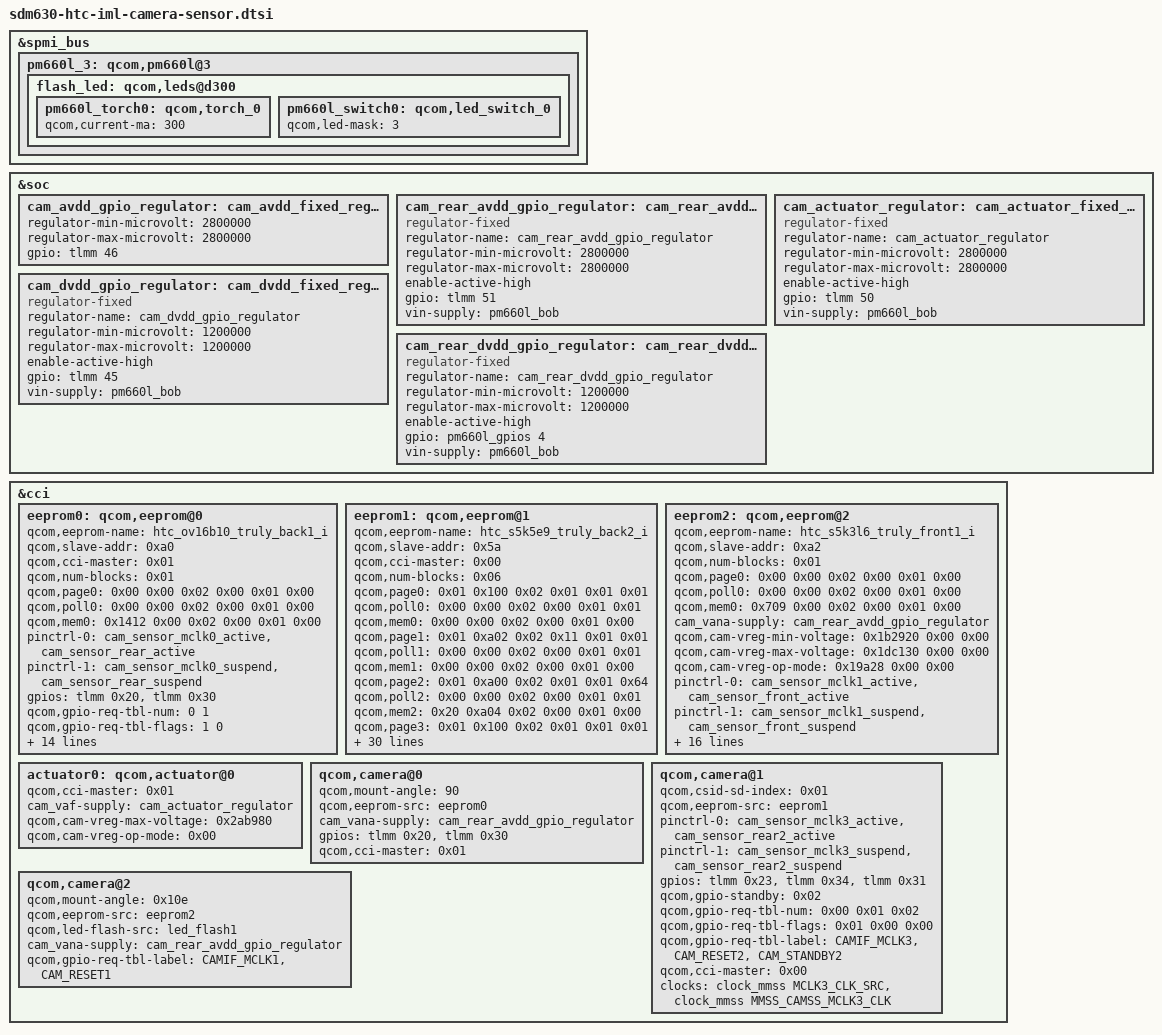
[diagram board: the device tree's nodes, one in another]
&spmi_bus {
	pm660l_3: qcom,pm660l@3 {
		flash_led: qcom,leds@d300 {
			pm660l_torch0: qcom,torch_0 {
				qcom,current-ma = <300>;
			};
			pm660l_switch0: qcom,led_switch_0 {
				qcom,led-mask = <3>;
			};
		};
	};
};

&soc {
	cam_avdd_gpio_regulator: cam_avdd_fixed_regulator {
		regulator-min-microvolt = <2800000>;
		regulator-max-microvolt = <2800000>;
		gpio = <&tlmm 46 0>;
	};
	cam_rear_avdd_gpio_regulator: cam_rear_avdd_fixed_regulator {
		compatible = "regulator-fixed";
		regulator-name = "cam_rear_avdd_gpio_regulator";
		regulator-min-microvolt = <2800000>;
		regulator-max-microvolt = <2800000>;
		enable-active-high;
		gpio = <&tlmm 51 0>;
		vin-supply = <&pm660l_bob>;
	};

	cam_actuator_regulator: cam_actuator_fixed_regulator {
		compatible = "regulator-fixed";
		regulator-name = "cam_actuator_regulator";
		regulator-min-microvolt = <2800000>;
		regulator-max-microvolt = <2800000>;
		enable-active-high;
		gpio = <&tlmm 50 0>;
		vin-supply = <&pm660l_bob>;
	};

	cam_dvdd_gpio_regulator: cam_dvdd_fixed_regulator {
		compatible = "regulator-fixed";
		regulator-name = "cam_dvdd_gpio_regulator";
		regulator-min-microvolt = <1200000>;
		regulator-max-microvolt = <1200000>;
		enable-active-high;
		gpio = <&tlmm 45 0>;
		vin-supply = <&pm660l_bob>;
	};

	cam_rear_dvdd_gpio_regulator: cam_rear_dvdd_fixed_regulator {
		compatible = "regulator-fixed";
		regulator-name = "cam_rear_dvdd_gpio_regulator";
		regulator-min-microvolt = <1200000>;
		regulator-max-microvolt = <1200000>;
		enable-active-high;
		gpio = <&pm660l_gpios 4 0>;
		vin-supply = <&pm660l_bob>;
	};
};

&cci {
	/* Only adding stuff that overwrites or extends the base SDM660 camera DTS */
	eeprom0: qcom,eeprom@0 {
		qcom,eeprom-name = "htc_ov16b10_truly_back1_i";
		qcom,slave-addr = <0xa0>;
		qcom,cci-master = <0x01>;
		qcom,num-blocks = <0x01>;
		qcom,page0 = <0x00 0x00 0x02 0x00 0x01 0x00>;
		qcom,poll0 = <0x00 0x00 0x02 0x00 0x01 0x00>;
		qcom,mem0 = <0x1412 0x00 0x02 0x00 0x01 0x00>;
		pinctrl-0 = <&cam_sensor_mclk0_active &cam_sensor_rear_active>;
		pinctrl-1 = <&cam_sensor_mclk0_suspend &cam_sensor_rear_suspend>;
		gpios = <&tlmm 0x20 0x00>,
		<&tlmm 0x30 0x00>;
		qcom,gpio-req-tbl-num = <0 1>;
		qcom,gpio-req-tbl-flags = <1 0>;
		qcom,gpio-req-tbl-label = "CAMIF_MCLK0", "CAM_RESET0";
		qcom,cam-power-seq-type = "sensor_gpio", "sensor_vreg",
		"sensor_vreg", "sensor_vreg",
		"sensor_clk", "sensor_gpio";
		qcom,cam-power-seq-val = "sensor_gpio_reset", "cam_vdig",
		"cam_vio", "cam_vana",
		"sensor_cam_mclk", "sensor_gpio_reset";
		qcom,cam-power-seq-cfg-val = <0x00 0x01 0x01 0x01 0x16e3600 0x01>;
		qcom,cam-power-seq-delay = <0x05 0x00 0x05 0x05 0x05 0x05>;
		cam_vana-supply = <&cam_rear_avdd_gpio_regulator>;
		qcom,i2c-freq-mode = <0x01>;
		/delete-property/ qcom,gpio-vaf;
	};
	
	eeprom1: qcom,eeprom@1 {
		qcom,eeprom-name = "htc_s5k5e9_truly_back2_i";
		qcom,slave-addr = <0x5a>;
		qcom,cci-master = <0x00>;
		qcom,num-blocks = <0x06>;
		qcom,page0 = <0x01 0x100 0x02 0x01 0x01 0x01>;
		qcom,poll0 = <0x00 0x00 0x02 0x00 0x01 0x01>;
		qcom,mem0 = <0x00 0x00 0x02 0x00 0x01 0x00>;
		qcom,page1 = <0x01 0xa02 0x02 0x11 0x01 0x01>;
		qcom,poll1 = <0x00 0x00 0x02 0x00 0x01 0x01>;
		qcom,mem1 = <0x00 0x00 0x02 0x00 0x01 0x00>;
		qcom,page2 = <0x01 0xa00 0x02 0x01 0x01 0x64>;
		qcom,poll2 = <0x00 0x00 0x02 0x00 0x01 0x01>;
		qcom,mem2 = <0x20 0xa04 0x02 0x00 0x01 0x00>;
		qcom,page3 = <0x01 0x100 0x02 0x01 0x01 0x01>;
		qcom,poll3 = <0x00 0x00 0x02 0x00 0x01 0x01>;
		qcom,mem3 = <0x00 0x00 0x02 0x00 0x01 0x00>;
		qcom,page4 = <0x01 0xa02 0x02 0x13 0x01 0x01>;
		qcom,poll4 = <0x00 0x00 0x02 0x00 0x01 0x01>;
		qcom,mem4 = <0x00 0x00 0x02 0x00 0x01 0x00>;
		qcom,page5 = <0x01 0xa00 0x02 0x01 0x01 0x64>;
		qcom,poll5 = <0x00 0x00 0x02 0x00 0x01 0x01>;
		qcom,mem5 = <0x20 0xa04 0x02 0x00 0x01 0x00>;
		pinctrl-0 = <&cam_sensor_mclk3_active &cam_sensor_rear2_active>;
		pinctrl-1 = <&cam_sensor_mclk3_suspend &cam_sensor_rear2_suspend>;
		gpios = <&tlmm 0x23 0x00>,
		<&tlmm 0x31 0x00>;
		qcom,gpio-req-tbl-num = <0 1>;
		qcom,gpio-req-tbl-flags = <1 0>;
		qcom,gpio-req-tbl-label = "CAMIF_MCLK3", "CAM_RESET1";
		qcom,cam-power-seq-type = "sensor_gpio", "sensor_vreg",
		"sensor_vreg", "sensor_vreg",
		"sensor_clk", "sensor_gpio";
		qcom,cam-power-seq-val = "sensor_gpio_reset", "cam_vdig",
		"cam_vio", "cam_vana",
		"sensor_cam_mclk", "sensor_gpio_reset";
		qcom,cam-power-seq-cfg-val = <0x00 0x01 0x01 0x01 0x16e3600 0x01>;
		qcom,cam-power-seq-delay = <0x01 0x05 0x05 0x05 0x01 0x0a>;
		qcom,i2c-freq-mode = <0x01>;
		clocks = <&clock_mmss MCLK3_CLK_SRC>,
		<&clock_mmss MMSS_CAMSS_MCLK3_CLK>;
	};
	
	eeprom2: qcom,eeprom@2 {
		qcom,eeprom-name = "htc_s5k3l6_truly_front1_i";
		qcom,slave-addr = <0xa2>;
		qcom,num-blocks = <0x01>;
		qcom,page0 = <0x00 0x00 0x02 0x00 0x01 0x00>;
		qcom,poll0 = <0x00 0x00 0x02 0x00 0x01 0x00>;
		qcom,mem0 = <0x709 0x00 0x02 0x00 0x01 0x00>;
		cam_vana-supply = <&cam_rear_avdd_gpio_regulator>;
		qcom,cam-vreg-min-voltage = <0x1b2920 0x00 0x00>;
		qcom,cam-vreg-max-voltage = <0x1dc130 0x00 0x00>;
		qcom,cam-vreg-op-mode = <0x19a28 0x00 0x00>;
		pinctrl-0 = <&cam_sensor_mclk1_active &cam_sensor_front_active>;
		pinctrl-1 = <&cam_sensor_mclk1_suspend &cam_sensor_front_suspend>;
		gpios = <0x77 0x21 0x00 0x77 0x2f 0x00>;
		/delete-property/ qcom,gpio-vana;
		/delete-property/ qcom,gpio-vaf;
		qcom,gpio-req-tbl-num = <0x00 0x01>;
		qcom,gpio-req-tbl-flags = <0x01 0x00>;
		qcom,gpio-req-tbl-label = "CAMIF_MCLK1", "CAM_RESET1";
		qcom,cam-power-seq-type = "sensor_gpio", "sensor_vreg",
		"sensor_vreg", "sensor_vreg",
		"sensor_clk", "sensor_gpio";
		qcom,cam-power-seq-val = "sensor_gpio_reset", "cam_vdig",
		"cam_vana", "cam_vio",
		"sensor_cam_mclk", "sensor_gpio_reset";
		qcom,cam-power-seq-cfg-val = <0x00 0x01 0x01 0x01 0x16e3600 0x01>;
		qcom,cam-power-seq-delay = <0x01 0x05 0x05 0x05 0x05 0x0a>;
		qcom,i2c-freq-mode = <0x01>;
	};
	
	/* NOTE: Stock DT supports more eeproms. But, these are the only ones for my specific device. People may add to this as necessary. */
	
	actuator0: qcom,actuator@0 {
		qcom,cci-master = <0x01>;
		cam_vaf-supply = <&cam_actuator_regulator>;
		qcom,cam-vreg-max-voltage = <0x2ab980>;
		qcom,cam-vreg-op-mode = <0x00>;
	};
	
	/delete-node/ qcom,actuator@1;
	/delete-node/ qcom,actuator@2;
	/delete-node/ qcom,ois@0;
	/delete-node/ qcom,tof@29;
	
	qcom,camera@0 {
		qcom,mount-angle = <90>;
		/delete-property/ qcom,ois-src;
		qcom,eeprom-src = <&eeprom0>; /* Add holitech eeprom src if needed like, <&eeprom0 &eeprom#> */
		cam_vana-supply = <&cam_rear_avdd_gpio_regulator>;
		gpios = <&tlmm 0x20 0x00>,
		<&tlmm 0x30 0x00>;
		qcom,cci-master = <0x01>;
	};
	
	qcom,camera@1 {
		qcom,csid-sd-index = <0x01>;
		qcom,eeprom-src = <&eeprom1>; /* Add holitech eeprom src if needed like, <&eeprom1 &eeprom#> */
		/delete-property/ qcom,actuator-src;
		pinctrl-0 = <&cam_sensor_mclk3_active
		&cam_sensor_rear2_active>;
		pinctrl-1 = <&cam_sensor_mclk3_suspend
		&cam_sensor_rear2_suspend>;
		gpios = <&tlmm 0x23 0x00>,
		<&tlmm 0x34 0x00>,
		<&tlmm 0x31 0x00>;
		qcom,gpio-standby = <0x02>;
		qcom,gpio-req-tbl-num = <0x00 0x01 0x02>;
		qcom,gpio-req-tbl-flags = <0x01 0x00 0x00>;
		qcom,gpio-req-tbl-label = "CAMIF_MCLK3",
		"CAM_RESET2",
		"CAM_STANDBY2";
		qcom,cci-master = <0x00>;
		clocks = <&clock_mmss MCLK3_CLK_SRC>,
		<&clock_mmss MMSS_CAMSS_MCLK3_CLK>;
	};
	
	qcom,camera@2 {
		qcom,mount-angle = <0x10e>;
		qcom,eeprom-src = <&eeprom2>; /* Add holitech eeprom src if needed like, <&eeprom2 &eeprom#> */
		/delete-property/ qcom,actuator-src;
		qcom,led-flash-src = <&led_flash1>;
		cam_vana-supply = <&cam_rear_avdd_gpio_regulator>;
		qcom,gpio-req-tbl-label = "CAMIF_MCLK1",
		"CAM_RESET1";
	};
	/delete-node/ qcom,camera@3;
};
